# TC37XPD register map
Vendor: Infineon; Series: ATVMC; File version: 100
CPU: other r0p0, little endian, MPU, FPU, vendor SysTick, 4 interrupt priority bits
Registers are 32-bit, read-write, reset 0x0 unless marked. A register's access mark holds for its fields unless they carry their own. Offsets are from the block's base; [hi:lo] are bit positions; {n}, {i} and the like mark numbered series.

## P34 — General Purpose I O Ports and Peripheral I O Lines
Base 0xF003C200
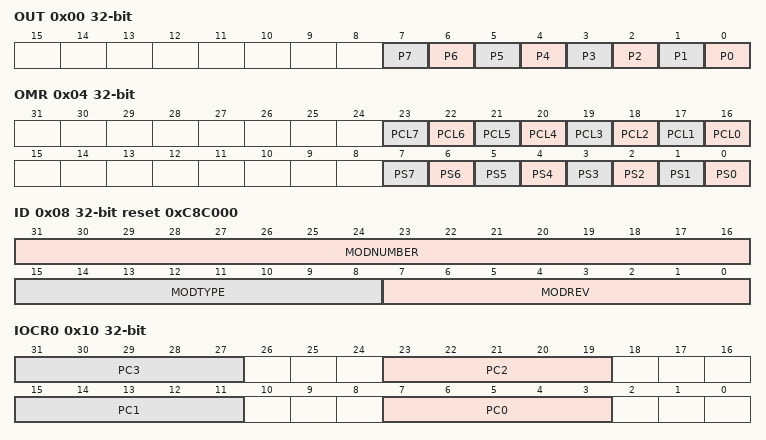
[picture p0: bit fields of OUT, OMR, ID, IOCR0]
0x00 OUT — Port 34 Output Register resetvalue={:0x0}
  [n] P{n} (n=0..7) — Output Bit 15. This bit determines the level at the output pin Pn.x if the output is selected as GPIO output. Pn.x can also be set or cleared by control bits of the Pn OMSR Pn OMCR or Pn OMR registers.
0x04 OMR wo — Port 34 Output Modification Register resetvalue={:0x0}
  [n+16] PCL{n} (n=0..7) — Clear Bit 15. Setting this bit will clear or toggle the corresponding bit in the port output register Pn OUT. Read as 0. The function of this bit is shown in Table .
  [n] PS{n} (n=0..7) — Set Bit 15. Setting this bit will set or toggle the corresponding bit in the port output register Pn OUT. Read as 0. The function of this bit is shown in Table .
0x08 ID ro reset 0xC8C000 (reset mask 0xFFFFFF00) — Port 34 Identification Register resetvalue={:0x0C8C000}
  [31:16] MODNUMBER — Module Number. This bit field defines the module identification number. The value for the Ports module is 00C8
  [15:8] MODTYPE — Module Type. This bit field is C0 H . It defines a 32 bit module
  [7:0] MODREV — Module Revision Number. This bit field indicates the revision number of the TC39x module 01 H 160 160 first revision .
0x10 IOCR0 (reset mask 0xEFEFEFEF) — Port 34 Input Output Control Register 0 resetvalue={:0x0,:0x0,:0x10101010,:0x10101010}
  [8n+7:8n+3] PC{n} (n=0..3) — Port Control for Pin 3. This bit field defines the Port n line x functionality according to Table only input selection apply.
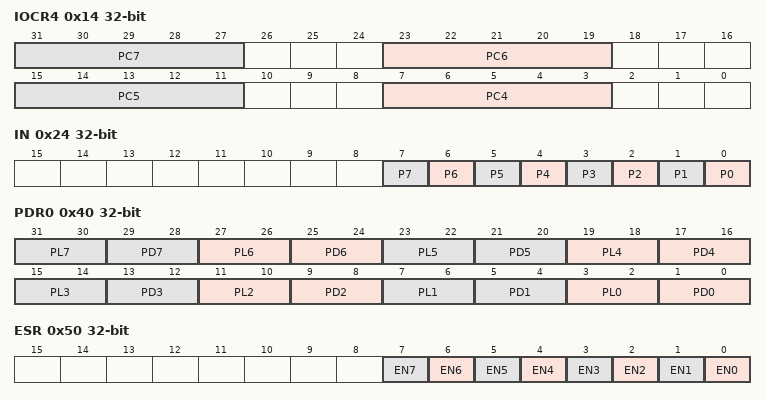
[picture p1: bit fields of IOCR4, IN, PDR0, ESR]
0x14 IOCR4 (reset mask 0xEFEFEFEF) — Port 34 Input Output Control Register 4 resetvalue={:0x0,:0x0,:0x10101010,:0x10101010}
  [8n-25:8n-29] PC{n} (n=4..7) — Port Control for Port 34 Pin 7. This bit field defines the Port n line x functionality according to Table only input selection apply.
0x24 IN ro (reset mask 0xFFFFFF00) — Port 34 Input Register resetvalue={:0x0}
  [n] P{n} (n=0..7) — Input Bit 15. This bit indicates the level at the input pin Pn.x.
0x40 PDR0 reset not defined — Port 34 Pad Driver Mode Register 0 resetvalue={:0x0,:0x0,After SSW execution:0x22222222,After SSW execution:0x22222222}
  [4n+3:4n+2] PL{n} (n=0..7) — Pad Level Selection for Pin 7
  [4n+1:4n] PD{n} (n=0..7) — Pad Driver Mode for Pin 7
0x50 ESR — Port 34 Emergency Stop Register resetvalue={:0x0}
  [n] EN{n} (n=0..7) — Emergency Stop Enable for Pin 15. This bit enables the emergency stop function for all GPIO lines. If the emergency stop condition is met and enabled the output selection is automatically switched from alternate output function to GPIO input function.
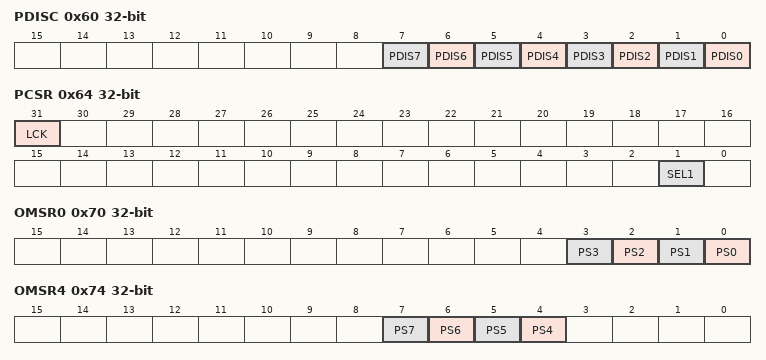
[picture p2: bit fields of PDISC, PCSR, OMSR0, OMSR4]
0x60 PDISC (reset mask 0xFFFFFF00) — Port 34 Pin Function Decision Control Register resetvalue={:0x0,:0x0,After SSW execution:0x0,After SSW execution:0x0}
  [n] PDIS{n} (n=0..7) — Pin Function Decision Control for Pin 15. This bit selects the function of the port pad.
0x64 PCSR access per field — Port 34 Pin Controller Select Register resetvalue={:0x0}
  [31] LCK ro — Lock Status. This bit indicates if the register can be updated with a new value or if the register is locked due to an ongoing transfer to the SCR and a write action from the bus has no effect. In Ports without SCR overlay this bit is always 0 .
  [1] SEL1 rw — Output Select for Pin 15. This bit enables or disables SCR control.
0x70 OMSR0 wo — Port 34 Output Modification Set Register 0 resetvalue={:0x0}
  [n] PS{n} (n=0..3) — Set Bit 3. Setting this bit will set the corresponding bit in the port output register Pn OUT. Read as 0.
0x74 OMSR4 wo — Port 34 Output Modification Set Register 4 resetvalue={:0x0}
  [n] PS{n} (n=4..7) — Set Bit 7. Setting this bit will set the corresponding bit in the port output register Pn OUT. Read as 0.
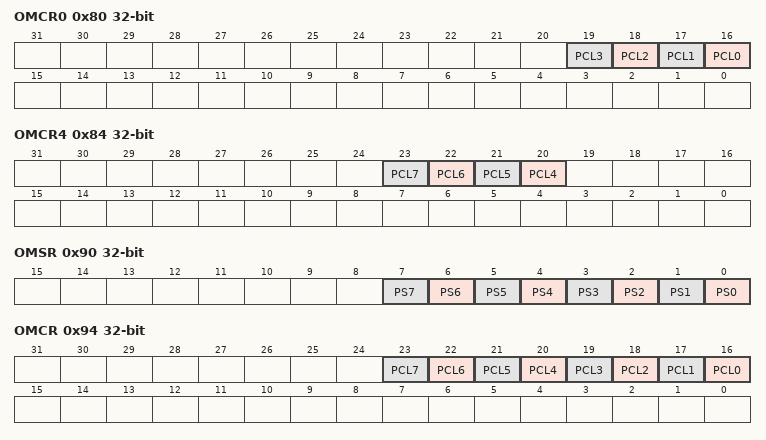
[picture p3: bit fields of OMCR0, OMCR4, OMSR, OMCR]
0x80 OMCR0 wo — Port 34 Output Modification Clear Register 0 resetvalue={:0x0}
  [n+16] PCL{n} (n=0..3) — Clear Bit 3. Setting this bit will clear the corresponding bit in the port output register Pn OUT. Read as 0.
0x84 OMCR4 wo — Port 34 Output Modification Clear Register 4 resetvalue={:0x0}
  [n+16] PCL{n} (n=4..7) — Clear Bit 7. Setting this bit will clear the corresponding bit in the port output register Pn OUT. Read as 0.
0x90 OMSR wo — Port 34 Output Modification Set Register resetvalue={:0x0}
  [n] PS{n} (n=0..7) — Set Bit 15. Setting this bit will set the corresponding bit in the port output register Pn OUT. Read as 0.
0x94 OMCR wo — Port 34 Output Modification Clear Register resetvalue={:0x0}
  [n+16] PCL{n} (n=0..7) — Clear Bit 15. Setting this bit will clear the corresponding bit in the port output register Pn OUT. Read as 0.
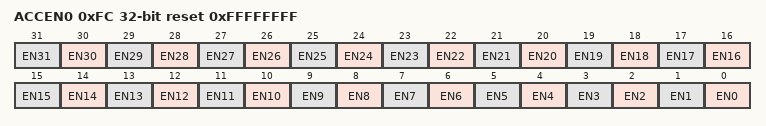
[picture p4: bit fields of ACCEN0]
0xFC ACCEN0 reset 0xFFFFFFFF — Port 34 Access Enable Register 0 resetvalue={:0x0FFFFFFFF}
  [n] EN{n} (n=0..31) — Access Enable for Master TAG ID 31. This bit enables write access to the module kernel addresses for transactions with the Master TAG ID n
